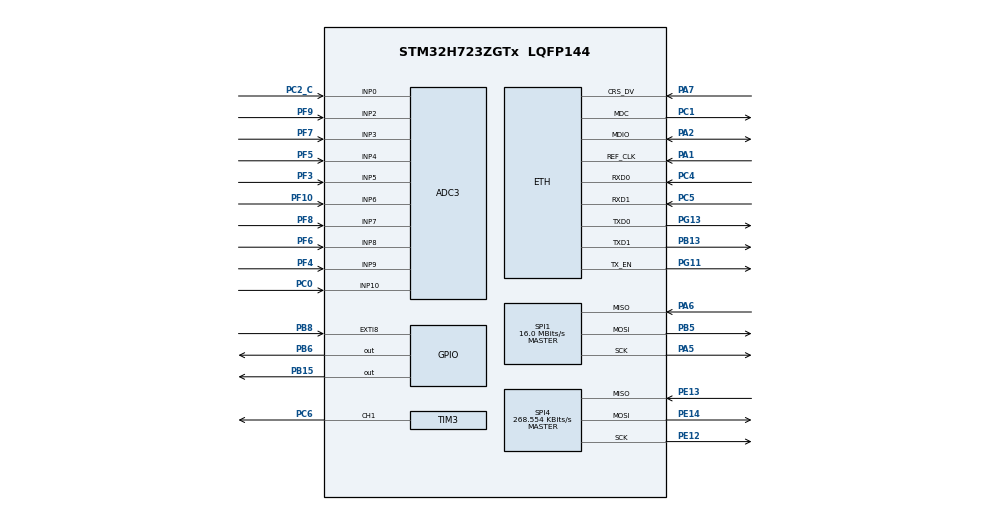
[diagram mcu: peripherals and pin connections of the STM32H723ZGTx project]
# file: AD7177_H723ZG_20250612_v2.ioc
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ADC3.Channel-0\#ChannelRegularConversion=ADC_CHANNEL_10
ADC3.Channel-1\#ChannelRegularConversion=ADC_CHANNEL_0
ADC3.Channel-10\#ChannelRegularConversion=ADC_CHANNEL_VREFINT
ADC3.Channel-2\#ChannelRegularConversion=ADC_CHANNEL_6
ADC3.Channel-3\#ChannelRegularConversion=ADC_CHANNEL_9
ADC3.Channel-4\#ChannelRegularConversion=ADC_CHANNEL_4
ADC3.Channel-5\#ChannelRegularConversion=ADC_CHANNEL_8
ADC3.Channel-6\#ChannelRegularConversion=ADC_CHANNEL_5
ADC3.Channel-7\#ChannelRegularConversion=ADC_CHANNEL_7
ADC3.Channel-8\#ChannelRegularConversion=ADC_CHANNEL_3
ADC3.Channel-9\#ChannelRegularConversion=ADC_CHANNEL_2
ADC3.DMAContinuousRequests=ENABLE
ADC3.EOCSelection=ADC_EOC_SEQ_CONV
ADC3.ExternalTrigConv=ADC_EXTERNALTRIG_T3_TRGO
ADC3.NbrOfConversion=11
ADC3.NbrOfConversionFlag=1
ADC3.OffsetNumber-0\#ChannelRegularConversion=ADC_OFFSET_NONE
ADC3.OffsetNumber-1\#ChannelRegularConversion=ADC_OFFSET_NONE
ADC3.OffsetNumber-10\#ChannelRegularConversion=ADC_OFFSET_NONE
ADC3.OffsetNumber-2\#ChannelRegularConversion=ADC_OFFSET_NONE
ADC3.OffsetNumber-3\#ChannelRegularConversion=ADC_OFFSET_NONE
ADC3.OffsetNumber-4\#ChannelRegularConversion=ADC_OFFSET_NONE
ADC3.OffsetNumber-5\#ChannelRegularConversion=ADC_OFFSET_NONE
ADC3.OffsetNumber-6\#ChannelRegularConversion=ADC_OFFSET_NONE
ADC3.OffsetNumber-7\#ChannelRegularConversion=ADC_OFFSET_NONE
ADC3.OffsetNumber-8\#ChannelRegularConversion=ADC_OFFSET_NONE
ADC3.OffsetNumber-9\#ChannelRegularConversion=ADC_OFFSET_NONE
ADC3.OffsetSign-0\#ChannelRegularConversion=ADC3_OFFSET_SIGN_NEGATIVE
ADC3.OffsetSign-1\#ChannelRegularConversion=ADC3_OFFSET_SIGN_NEGATIVE
ADC3.OffsetSign-10\#ChannelRegularConversion=ADC3_OFFSET_SIGN_NEGATIVE
ADC3.OffsetSign-2\#ChannelRegularConversion=ADC3_OFFSET_SIGN_NEGATIVE
ADC3.OffsetSign-3\#ChannelRegularConversion=ADC3_OFFSET_SIGN_NEGATIVE
ADC3.OffsetSign-4\#ChannelRegularConversion=ADC3_OFFSET_SIGN_NEGATIVE
ADC3.OffsetSign-5\#ChannelRegularConversion=ADC3_OFFSET_SIGN_NEGATIVE
ADC3.OffsetSign-6\#ChannelRegularConversion=ADC3_OFFSET_SIGN_NEGATIVE
ADC3.OffsetSign-7\#ChannelRegularConversion=ADC3_OFFSET_SIGN_NEGATIVE
ADC3.OffsetSign-8\#ChannelRegularConversion=ADC3_OFFSET_SIGN_NEGATIVE
ADC3.OffsetSign-9\#ChannelRegularConversion=ADC3_OFFSET_SIGN_NEGATIVE
ADC3.OversamplingMode=ENABLE
ADC3.Rank-0\#ChannelRegularConversion=1
ADC3.Rank-1\#ChannelRegularConversion=2
ADC3.Rank-10\#ChannelRegularConversion=11
ADC3.Rank-2\#ChannelRegularConversion=3
ADC3.Rank-3\#ChannelRegularConversion=4
ADC3.Rank-4\#ChannelRegularConversion=5
ADC3.Rank-5\#ChannelRegularConversion=6
ADC3.Rank-6\#ChannelRegularConversion=7
ADC3.Rank-7\#ChannelRegularConversion=8
ADC3.Rank-8\#ChannelRegularConversion=9
ADC3.Rank-9\#ChannelRegularConversion=10
ADC3.Ratio=ADC3_OVERSAMPLING_RATIO_128
ADC3.RightBitShift=ADC_RIGHTBITSHIFT_7
ADC3.SamplingTime-0\#ChannelRegularConversion=ADC3_SAMPLETIME_640CYCLES_5
ADC3.SamplingTime-1\#ChannelRegularConversion=ADC3_SAMPLETIME_640CYCLES_5
ADC3.SamplingTime-10\#ChannelRegularConversion=ADC3_SAMPLETIME_640CYCLES_5
ADC3.SamplingTime-2\#ChannelRegularConversion=ADC3_SAMPLETIME_640CYCLES_5
ADC3.SamplingTime-3\#ChannelRegularConversion=ADC3_SAMPLETIME_640CYCLES_5
ADC3.SamplingTime-4\#ChannelRegularConversion=ADC3_SAMPLETIME_640CYCLES_5
ADC3.SamplingTime-5\#ChannelRegularConversion=ADC3_SAMPLETIME_640CYCLES_5
ADC3.SamplingTime-6\#ChannelRegularConversion=ADC3_SAMPLETIME_640CYCLES_5
ADC3.SamplingTime-7\#ChannelRegularConversion=ADC3_SAMPLETIME_640CYCLES_5
ADC3.SamplingTime-8\#ChannelRegularConversion=ADC3_SAMPLETIME_640CYCLES_5
ADC3.SamplingTime-9\#ChannelRegularConversion=ADC3_SAMPLETIME_640CYCLES_5
Bdma.ADC3.0.Direction=DMA_PERIPH_TO_MEMORY
Bdma.ADC3.0.EventEnable=DISABLE
Bdma.ADC3.0.Instance=BDMA_Channel0
Bdma.ADC3.0.MemDataAlignment=DMA_MDATAALIGN_HALFWORD
Bdma.ADC3.0.MemInc=DMA_MINC_ENABLE
Bdma.ADC3.0.Mode=DMA_CIRCULAR
Bdma.ADC3.0.PeriphDataAlignment=DMA_PDATAALIGN_HALFWORD
Bdma.ADC3.0.PeriphInc=DMA_PINC_DISABLE
Bdma.ADC3.0.Polarity=HAL_DMAMUX_REQ_GEN_RISING
Bdma.ADC3.0.Priority=DMA_PRIORITY_HIGH
Bdma.ADC3.0.RequestNumber=1
Bdma.ADC3.0.SignalID=NONE
Bdma.ADC3.0.SyncEnable=DISABLE
Bdma.ADC3.0.SyncPolarity=HAL_DMAMUX_SYNC_NO_EVENT
Bdma.ADC3.0.SyncRequestNumber=1
Bdma.ADC3.0.SyncSignalID=NONE
Bdma.Request0=ADC3
Bdma.RequestsNb=1
CORTEX_M7.AccessPermission-Cortex_Memory_Protection_Unit_Region1_Settings=MPU_REGION_FULL_ACCESS
CORTEX_M7.AccessPermission-Cortex_Memory_Protection_Unit_Region2_Settings=MPU_REGION_FULL_ACCESS
CORTEX_M7.AccessPermission-Cortex_Memory_Protection_Unit_Region3_Settings=MPU_REGION_FULL_ACCESS
CORTEX_M7.BaseAddress-Cortex_Memory_Protection_Unit_Region1_Settings=0x30000000
CORTEX_M7.BaseAddress-Cortex_Memory_Protection_Unit_Region2_Settings=0x30000200
CORTEX_M7.BaseAddress-Cortex_Memory_Protection_Unit_Region3_Settings=0x38000000
CORTEX_M7.CPU_DCache=Enabled
CORTEX_M7.CPU_ICache=Enabled
CORTEX_M7.DisableExec-Cortex_Memory_Protection_Unit_Region0_Settings=MPU_INSTRUCTION_ACCESS_DISABLE
CORTEX_M7.DisableExec-Cortex_Memory_Protection_Unit_Region1_Settings=MPU_INSTRUCTION_ACCESS_DISABLE
CORTEX_M7.DisableExec-Cortex_Memory_Protection_Unit_Region2_Settings=MPU_INSTRUCTION_ACCESS_DISABLE
CORTEX_M7.Enable-Cortex_Memory_Protection_Unit_Region0_Settings=MPU_REGION_ENABLE
CORTEX_M7.Enable-Cortex_Memory_Protection_Unit_Region1_Settings=MPU_REGION_ENABLE
CORTEX_M7.Enable-Cortex_Memory_Protection_Unit_Region2_Settings=MPU_REGION_ENABLE
CORTEX_M7.Enable-Cortex_Memory_Protection_Unit_Region3_Settings=MPU_REGION_ENABLE
CORTEX_M7.IsBufferable-Cortex_Memory_Protection_Unit_Region1_Settings=MPU_ACCESS_BUFFERABLE
CORTEX_M7.IsBufferable-Cortex_Memory_Protection_Unit_Region3_Settings=MPU_ACCESS_BUFFERABLE
CORTEX_M7.IsShareable-Cortex_Memory_Protection_Unit_Region0_Settings=MPU_ACCESS_SHAREABLE
CORTEX_M7.IsShareable-Cortex_Memory_Protection_Unit_Region1_Settings=MPU_ACCESS_SHAREABLE
CORTEX_M7.IsShareable-Cortex_Memory_Protection_Unit_Region2_Settings=MPU_ACCESS_NOT_SHAREABLE
CORTEX_M7.IsShareable-Cortex_Memory_Protection_Unit_Region3_Settings=MPU_ACCESS_SHAREABLE
CORTEX_M7.MPU_Control=MPU_PRIVILEGED_DEFAULT
CORTEX_M7.Size-Cortex_Memory_Protection_Unit_Region0_Settings=MPU_REGION_SIZE_4GB
CORTEX_M7.Size-Cortex_Memory_Protection_Unit_Region1_Settings=MPU_REGION_SIZE_1KB
CORTEX_M7.Size-Cortex_Memory_Protection_Unit_Region2_Settings=MPU_REGION_SIZE_64KB
CORTEX_M7.Size-Cortex_Memory_Protection_Unit_Region3_Settings=MPU_REGION_SIZE_16KB
CORTEX_M7.SubRegionDisable-Cortex_Memory_Protection_Unit_Region0_Settings=0x87
CORTEX_M7.TypeExtField-Cortex_Memory_Protection_Unit_Region1_Settings=MPU_TEX_LEVEL0
CORTEX_M7.TypeExtField-Cortex_Memory_Protection_Unit_Region2_Settings=MPU_TEX_LEVEL1
Dma.Request0=SPI4_TX
Dma.Request1=SPI4_RX
Dma.Request2=SPI1_RX
Dma.Request3=SPI1_TX
Dma.SPI1_RX.2.Direction=DMA_PERIPH_TO_MEMORY
Dma.SPI1_RX.2.EventEnable=DISABLE
Dma.SPI1_RX.2.FIFOMode=DMA_FIFOMODE_DISABLE
Dma.SPI1_RX.2.Instance=DMA1_Stream2
Dma.SPI1_RX.2.MemDataAlignment=DMA_MDATAALIGN_BYTE
Dma.SPI1_RX.2.MemInc=DMA_MINC_ENABLE
Dma.SPI1_RX.2.Mode=DMA_NORMAL
Dma.SPI1_RX.2.PeriphDataAlignment=DMA_PDATAALIGN_BYTE
Dma.SPI1_RX.2.PeriphInc=DMA_PINC_DISABLE
Dma.SPI1_RX.2.Polarity=HAL_DMAMUX_REQ_GEN_RISING
Dma.SPI1_RX.2.Priority=DMA_PRIORITY_VERY_HIGH
Dma.SPI1_RX.2.RequestNumber=1
Dma.SPI1_RX.2.SignalID=NONE
Dma.SPI1_RX.2.SyncEnable=DISABLE
Dma.SPI1_RX.2.SyncPolarity=HAL_DMAMUX_SYNC_NO_EVENT
Dma.SPI1_RX.2.SyncRequestNumber=1
Dma.SPI1_RX.2.SyncSignalID=NONE
Dma.SPI1_TX.3.Direction=DMA_MEMORY_TO_PERIPH
Dma.SPI1_TX.3.EventEnable=DISABLE
Dma.SPI1_TX.3.FIFOMode=DMA_FIFOMODE_DISABLE
Dma.SPI1_TX.3.Instance=DMA1_Stream3
Dma.SPI1_TX.3.MemDataAlignment=DMA_MDATAALIGN_BYTE
Dma.SPI1_TX.3.MemInc=DMA_MINC_ENABLE
Dma.SPI1_TX.3.Mode=DMA_NORMAL
Dma.SPI1_TX.3.PeriphDataAlignment=DMA_PDATAALIGN_BYTE
Dma.SPI1_TX.3.PeriphInc=DMA_PINC_DISABLE
Dma.SPI1_TX.3.Polarity=HAL_DMAMUX_REQ_GEN_RISING
Dma.SPI1_TX.3.Priority=DMA_PRIORITY_VERY_HIGH
Dma.SPI1_TX.3.RequestNumber=1
Dma.SPI1_TX.3.SignalID=NONE
Dma.SPI1_TX.3.SyncEnable=DISABLE
Dma.SPI1_TX.3.SyncPolarity=HAL_DMAMUX_SYNC_NO_EVENT
Dma.SPI1_TX.3.SyncRequestNumber=1
Dma.SPI1_TX.3.SyncSignalID=NONE
Dma.SPI4_RX.1.Direction=DMA_PERIPH_TO_MEMORY
Dma.SPI4_RX.1.EventEnable=DISABLE
Dma.SPI4_RX.1.FIFOMode=DMA_FIFOMODE_DISABLE
Dma.SPI4_RX.1.Instance=DMA1_Stream1
Dma.SPI4_RX.1.MemDataAlignment=DMA_MDATAALIGN_BYTE
Dma.SPI4_RX.1.MemInc=DMA_MINC_ENABLE
Dma.SPI4_RX.1.Mode=DMA_NORMAL
Dma.SPI4_RX.1.PeriphDataAlignment=DMA_PDATAALIGN_BYTE
Dma.SPI4_RX.1.PeriphInc=DMA_PINC_DISABLE
Dma.SPI4_RX.1.Polarity=HAL_DMAMUX_REQ_GEN_RISING
Dma.SPI4_RX.1.Priority=DMA_PRIORITY_VERY_HIGH
Dma.SPI4_RX.1.RequestNumber=1
Dma.SPI4_RX.1.SignalID=NONE
Dma.SPI4_RX.1.SyncEnable=DISABLE
Dma.SPI4_RX.1.SyncPolarity=HAL_DMAMUX_SYNC_NO_EVENT
Dma.SPI4_RX.1.SyncRequestNumber=1
Dma.SPI4_RX.1.SyncSignalID=NONE
Dma.SPI4_TX.0.Direction=DMA_MEMORY_TO_PERIPH
Dma.SPI4_TX.0.EventEnable=DISABLE
Dma.SPI4_TX.0.FIFOMode=DMA_FIFOMODE_DISABLE
Dma.SPI4_TX.0.Instance=DMA1_Stream0
Dma.SPI4_TX.0.MemDataAlignment=DMA_MDATAALIGN_BYTE
Dma.SPI4_TX.0.MemInc=DMA_MINC_ENABLE
Dma.SPI4_TX.0.Mode=DMA_NORMAL
Dma.SPI4_TX.0.PeriphDataAlignment=DMA_PDATAALIGN_BYTE
Dma.SPI4_TX.0.PeriphInc=DMA_PINC_DISABLE
Dma.SPI4_TX.0.Polarity=HAL_DMAMUX_REQ_GEN_RISING
Dma.SPI4_TX.0.Priority=DMA_PRIORITY_VERY_HIGH
Dma.SPI4_TX.0.RequestNumber=1
Dma.SPI4_TX.0.SignalID=NONE
Dma.SPI4_TX.0.SyncEnable=DISABLE
Dma.SPI4_TX.0.SyncPolarity=HAL_DMAMUX_SYNC_NO_EVENT
Dma.SPI4_TX.0.SyncRequestNumber=1
Dma.SPI4_TX.0.SyncSignalID=NONE
ETH.MediaInterface=HAL_ETH_RMII_MODE
ETH.RxBufferAddress=0x30000200
ETH.TxDescAddress=0x30000060
FREERTOS.INCLUDE_vTaskDelayUntil=1
FREERTOS.Tasks01=defaultTask,24,256,StartDefaultTask,Default,NULL,Dynamic,NULL,NULL;ethernetTask,40,256,startEthernetTask,Default,NULL,Dynamic,NULL,NULL
FREERTOS.configTOTAL_HEAP_SIZE=30720
FREERTOS.configUSE_NEWLIB_REENTRANT=1
LWIP.BSP.number=1
LWIP.GATEWAY_ADDRESS=010.020.001.003
LWIP.IP_ADDRESS=010.020.003.003
LWIP.LWIP_DHCP=0
LWIP.LWIP_RAM_HEAP_POINTER=0x30000200
LWIP.MEM_SIZE=10*1024
LWIP.NETMASK_ADDRESS=255.255.000.000
LWIP.TCP_MSS=1460
LWIP.TCP_SND_BUF=5840
LWIP.TCP_SND_QUEUELEN=16
LWIP.Version=v2.1.2_Cube
LWIP0.BSP.STBoard=false
LWIP0.BSP.api=BSP_COMPONENT_DRIVER
LWIP0.BSP.component=LAN8742
LWIP0.BSP.instance=LAN8742
LWIP0.BSP.name=Driver_PHY
LWIP0.BSP.semaphore=S_LAN8742
LWIP0.BSP.solution=LAN8742
Mcu.Family=STM32H7
Mcu.Name=STM32H723ZGTx
Mcu.Package=LQFP144
NVIC.BDMA_Channel0_IRQn=true\:5\:0\:false\:false\:true\:true\:false\:true\:true
NVIC.DMA1_Stream0_IRQn=true\:5\:0\:false\:false\:true\:true\:false\:true\:true
NVIC.DMA1_Stream1_IRQn=true\:5\:0\:false\:false\:true\:true\:false\:true\:true
NVIC.DMA1_Stream2_IRQn=true\:5\:0\:false\:false\:true\:true\:false\:true\:true
NVIC.DMA1_Stream3_IRQn=true\:5\:0\:false\:false\:true\:true\:false\:true\:true
NVIC.ETH_IRQn=true\:5\:0\:false\:false\:true\:true\:true\:true\:true
NVIC.EXTI9_5_IRQn=true\:6\:0\:true\:false\:true\:true\:true\:true\:true
NVIC.PriorityGroup=NVIC_PRIORITYGROUP_4
NVIC.SPI1_IRQn=true\:5\:0\:false\:false\:true\:true\:true\:true\:true
NVIC.SPI4_IRQn=true\:5\:0\:false\:false\:true\:true\:false\:true\:true
NVIC.TIM2_IRQn=true\:5\:0\:false\:false\:true\:false\:true\:true\:true
NVIC.TIM6_DAC_IRQn=true\:15\:0\:false\:false\:true\:false\:false\:true\:true
NVIC.TimeBase=TIM6_DAC_IRQn
NVIC.TimeBaseIP=TIM6
PA1.GPIO_Speed=GPIO_SPEED_FREQ_VERY_HIGH
PA1.Mode=RMII
PA1.Signal=ETH_REF_CLK
PA2.GPIO_Speed=GPIO_SPEED_FREQ_VERY_HIGH
PA2.Mode=RMII
PA2.Signal=ETH_MDIO
PA5.Mode=Full_Duplex_Master
PA5.Signal=SPI1_SCK
PA6.Mode=Full_Duplex_Master
PA6.Signal=SPI1_MISO
PA7.GPIO_Speed=GPIO_SPEED_FREQ_VERY_HIGH
PA7.Mode=RMII
PA7.Signal=ETH_CRS_DV
PB13.GPIO_Speed=GPIO_SPEED_FREQ_VERY_HIGH
PB13.Mode=RMII
PB13.Signal=ETH_TXD1
PB15.Signal=GPIO_Output
PB5.Mode=Full_Duplex_Master
PB5.Signal=SPI1_MOSI
PB6.GPIO_Speed=GPIO_SPEED_FREQ_VERY_HIGH
PB6.Signal=GPIO_Output
PB8.GPIO_ModeDefaultEXTI=GPIO_MODE_IT_FALLING
PB8.GPIO_PuPd=GPIO_PULLUP
PB8.Signal=GPXTI8
PC0.Signal=ADCx_INP10
PC1.GPIO_Speed=GPIO_SPEED_FREQ_VERY_HIGH
PC1.Mode=RMII
PC1.Signal=ETH_MDC
PC2_C.Mode=IN0-Single-Ended
PC2_C.Signal=ADC3_INP0
PC4.GPIO_Speed=GPIO_SPEED_FREQ_VERY_HIGH
PC4.Mode=RMII
PC4.Signal=ETH_RXD0
PC5.GPIO_Speed=GPIO_SPEED_FREQ_VERY_HIGH
PC5.Mode=RMII
PC5.Signal=ETH_RXD1
PC6.GPIO_PuPd=GPIO_PULLUP
PC6.Signal=S_TIM3_CH1
PE12.Mode=Full_Duplex_Master
PE12.Signal=SPI4_SCK
PE13.Mode=Full_Duplex_Master
PE13.Signal=SPI4_MISO
PE14.Mode=Full_Duplex_Master
PE14.Signal=SPI4_MOSI
PF10.Mode=IN6-Single-Ended
PF10.Signal=ADC3_INP6
PF3.Mode=IN5-Single-Ended
PF3.Signal=ADC3_INP5
PF4.Mode=IN9-Single-Ended
PF4.Signal=ADC3_INP9
PF5.Mode=IN4-Single-Ended
PF5.Signal=ADC3_INP4
PF6.Mode=IN8-Single-Ended
PF6.Signal=ADC3_INP8
PF7.Mode=IN3-Single-Ended
PF7.Signal=ADC3_INP3
PF8.Mode=IN7-Single-Ended
PF8.Signal=ADC3_INP7
PF9.Mode=IN2-Single-Ended
PF9.Signal=ADC3_INP2
PG11.GPIO_Speed=GPIO_SPEED_FREQ_VERY_HIGH
PG11.Mode=RMII
PG11.Signal=ETH_TX_EN
PG13.GPIO_Speed=GPIO_SPEED_FREQ_VERY_HIGH
PG13.Mode=RMII
PG13.Signal=ETH_TXD0
PH0-OSC_IN.Mode=HSE-External-Clock-Source
PH0-OSC_IN.Signal=RCC_OSC_IN
ProjectManager.HeapSize=0x200
ProjectManager.StackSize=0x400
ProjectManager.TargetToolchain=STM32CubeIDE
RCC.ADCFreq_Value=12500000
RCC.APB1Freq_Value=137500000
RCC.APB2Freq_Value=68750000
RCC.APB3Freq_Value=137500000
RCC.APB4Freq_Value=137500000
RCC.CortexFreq_Value=550000000
RCC.D1PPRE=RCC_APB3_DIV2
RCC.D2PPRE1=RCC_APB1_DIV2
RCC.D2PPRE2=RCC_APB2_DIV4
RCC.D3PPRE=RCC_APB4_DIV2
RCC.DIVM1=4
RCC.DIVM2=1
RCC.DIVN1=275
RCC.DIVN2=25
RCC.DIVP1=1
RCC.DIVP2=16
RCC.DIVQ1=4
RCC.DIVQ2=16
RCC.HCLKFreq_Value=275000000
RCC.HPRE=RCC_HCLK_DIV2
RCC.HSE_VALUE=8000000
RCC.PLLFRACN=0
RCC.PLLSourceVirtual=RCC_PLLSOURCE_HSE
RCC.SPI123CLockSelection=RCC_SPI123CLKSOURCE_CLKP
RCC.SYSCLKFreq_VALUE=550000000
RCC.SYSCLKSource=RCC_SYSCLKSOURCE_PLLCLK
RCC.USBCLockSelection=RCC_USBCLKSOURCE_HSI48
RCC.USBFreq_Value=48000000
SH.ADCx_INP10.0=ADC3_INP10,IN10-Single-Ended
SH.S_TIM3_CH1.0=TIM3_CH1,PWM Generation1 CH1
SPI1.BaudRatePrescaler=SPI_BAUDRATEPRESCALER_4
SPI1.CLKPhase=SPI_PHASE_2EDGE
SPI1.CLKPolarity=SPI_POLARITY_HIGH
SPI1.CalculateBaudRate=16.0 MBits/s
SPI1.DataSize=SPI_DATASIZE_8BIT
SPI1.Direction=SPI_DIRECTION_2LINES
SPI1.MasterKeepIOState=SPI_MASTER_KEEP_IO_STATE_ENABLE
SPI1.Mode=SPI_MODE_MASTER
SPI1.VirtualType=VM_MASTER
SPI4.BaudRatePrescaler=SPI_BAUDRATEPRESCALER_256
SPI4.CLKPhase=SPI_PHASE_2EDGE
SPI4.CLKPolarity=SPI_POLARITY_HIGH
SPI4.CalculateBaudRate=268.554 KBits/s
SPI4.DataSize=SPI_DATASIZE_8BIT
SPI4.Direction=SPI_DIRECTION_2LINES
SPI4.MasterKeepIOState=SPI_MASTER_KEEP_IO_STATE_DISABLE
SPI4.Mode=SPI_MODE_MASTER
SPI4.VirtualType=VM_MASTER
TIM1.Channel-Output\ Compare1\ No\ Output=TIM_CHANNEL_1
TIM1.Prescaler=1375-1
TIM2.Channel-PWM\ Generation1\ No\ Output=TIM_CHANNEL_1
TIM2.Period=1000-1
TIM2.Prescaler=275-1
TIM2.TIM_MasterOutputTrigger=TIM_TRGO_RESET
TIM23.Prescaler=275-1
TIM3.Channel-PWM\ Generation1\ CH1=TIM_CHANNEL_1
TIM3.OCPolarity_1=TIM_OCPOLARITY_HIGH
TIM3.Period=10000-1
TIM3.Prescaler=2750-1
TIM3.Pulse-PWM\ Generation1\ CH1=500
TIM3.TIM_MasterOutputTrigger=TIM_TRGO_UPDATE
VP_ADC3_Vref_Input.Mode=IN-Vrefint
VP_FREERTOS_VS_CMSIS_V2.Mode=CMSIS_V2
VP_LWIP_VS_Enabled.Mode=Enabled
VP_MEMORYMAP_VS_MEMORYMAP.Mode=CurAppReg
VP_SYS_VS_tim6.Mode=TIM6
VP_TIM1_VS_ClockSourceINT.Mode=Internal
VP_TIM1_VS_no_output1.Mode=Output Compare1 No Output
VP_TIM23_VS_ClockSourceINT.Mode=Internal
VP_TIM2_VS_ClockSourceINT.Mode=Internal
VP_TIM2_VS_no_output1.Mode=PWM Generation1 No Output
VP_TIM3_VS_ClockSourceINT.Mode=Internal
VREF+.Mode=InternalMode
VREF+.Signal=VREFBUF_OUT
VREFBUF.TrimmingMode=USER_TRIMMING
VREFBUF.TrimmingValue=18
board=NUCLEO-H723ZG

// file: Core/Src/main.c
/* USER CODE BEGIN Header */
/**
 ******************************************************************************
 * @file           : main.c
 * @brief          : Main program body
 ******************************************************************************
 * @attention
 *
 * Copyright (c) 2024 STMicroelectronics.
 * All rights reserved.
 *
 * This software is licensed under terms that can be found in the LICENSE file
 * in the root directory of this software component.
 * If no LICENSE file comes with this software, it is provided AS-IS.
 *
 ******************************************************************************
 */
/* USER CODE END Header */
#include "main.h"
#include "cmsis_os.h"
#include "lwip.h"

/* USER CODE BEGIN Includes */
#include "lwip/udp.h"
#include <string.h>
#include <stdbool.h>
#include <stddef.h>
#include "stm32h7xx_it.h"
#include "AD7177_registers.h"
#include "net_config.h"

/* USER CODE END Includes */

/* USER CODE BEGIN PD */

#define HK_SYNC_STR "HKPK"
#define HK_VERSION  1

#define ACCEL_SYNC_STR "ACCL"
#define ACCEL_VERSION  1

#define PKT_WORDS 601

/* USER CODE END PD */

ADC_HandleTypeDef hadc3;
DMA_HandleTypeDef hdma_adc3;

SPI_HandleTypeDef hspi1;
SPI_HandleTypeDef hspi4;
DMA_HandleTypeDef hdma_spi1_rx;
DMA_HandleTypeDef hdma_spi1_tx;
DMA_HandleTypeDef hdma_spi4_tx;
DMA_HandleTypeDef hdma_spi4_rx;

TIM_HandleTypeDef htim1;
TIM_HandleTypeDef htim2;
TIM_HandleTypeDef htim3;
TIM_HandleTypeDef htim23;

/* Definitions for defaultTask */
osThreadId_t defaultTaskHandle;
const osThreadAttr_t defaultTask_attributes = {
  .name = "defaultTask",
  .stack_size = 256 * 4,
  .priority = (osPriority_t) osPriorityNormal,
};
/* Definitions for ethernetTask */
osThreadId_t ethernetTaskHandle;
const osThreadAttr_t ethernetTask_attributes = {
  .name = "ethernetTask",
  .stack_size = 256 * 4,
  .priority = (osPriority_t) osPriorityHigh,
};
/* USER CODE BEGIN PV */
//PUT SETUP STUFF HERE

// Ping-pong packet buffers: each packet is 601 uint16_t words
#define PKT_WORDS 601
static uint16_t pkt_buf[2][PKT_WORDS];
static volatile uint8_t write_buf = 0;      // ISR writes into this buffer (0 or 1)
static volatile uint8_t ready_buf = 0xFF;   // Published by ISR when a packet is complete
static volatile uint16_t accum_words = 0;   // Words accumulated in current write_buf

uint8_t rxBuffer24bit[5];
static uint8_t g_txBuffer24bit_IT[5] = {AD7177_READ_DATA_REG, 0,0,0,0 };
// --- ADC3 ← DMA target buffer (one regular sequence worth of samples) ---
#define ADC3_SCAN_LEN (11u)   // Must match hadc3.Init.NbrOfConversion
// 32B align for D-Cache maintenance on STM32H7

__attribute__((section(".RAM_D3"), aligned(32))) volatile uint16_t adc3_dma_buf[ADC3_SCAN_LEN];

// Housekeeping latest snapshot captured at 110 Hz in the ADC DMA callback
typedef struct {
  uint32_t tick32;               // TIM23 snapshot
  uint16_t ch[ADC3_SCAN_LEN];    // 11 channels, raw 12-bit codes
} hk_snapshot_t;

typedef struct {
  uint8_t  sync[4];   // e.g. "HKPK"
  uint8_t  version;    // e.g. 1
  uint8_t  reserved[3];// pad to 8B boundary, room for flags
  uint32_t seq;
  uint32_t tick32;
  uint16_t ch[ADC3_SCAN_LEN];
} __attribute__((packed)) hk_pkt_t;

//Small accel data header for differentiating packet types
typedef struct {
  uint8_t  sync[4];     // "ACCL"
  uint8_t  version;     // e.g. 1
  uint8_t  reserved[3]; // pad to 8B
  // existing payload follows (spiData[0..600])
} __attribute__((packed)) accel_hdr_t;

static volatile hk_snapshot_t g_hk_latest;   // written in ISR, read by task
static uint32_t g_hk_seq = 0;                // 10 Hz packet sequence

volatile bool g_init_done = false;
volatile bool g_acc_send_req = false;
volatile bool g_hk_send_req = false;
volatile bool g_spi_inflight = false;

volatile uint32_t sampleNum = 0;

volatile uint32_t channel_data[4] = {0};      // Holds raw ADC values
volatile uint8_t  channel_ready[4] = {0};     // Flags to know when each channel has been updated

volatile uint32_t timer23val;

uint8_t resetSequence[8] = {0xFF, 0xFF, 0xFF, 0xFF, 0xFF, 0xFF, 0xFF, 0xFF};

/* USER CODE END PV */

void SystemClock_Config(void);
void PeriphCommonClock_Config(void);
static void MPU_Config(void);
static void MX_GPIO_Init(void);
static void MX_DMA_Init(void);
static void MX_BDMA_Init(void);
static void MX_TIM2_Init(void);
static void MX_SPI4_Init(void);
static void MX_TIM23_Init(void);
static void MX_TIM1_Init(void);
static void MX_SPI1_Init(void);
static void MX_TIM3_Init(void);
static void MX_ADC3_Init(void);
void StartDefaultTask(void *argument);
void startEthernetTask(void *argument);

/* USER CODE BEGIN PFP */
uint32_t AD7177_ReadRegister(uint8_t reg, uint8_t num_bytes);
void AD7177_WriteRegister(uint8_t reg, uint32_t value, uint8_t num_bytes);
void initializeAD7177Board();

/* USER CODE END PFP */

int main(void)
{

  /* MPU Configuration--------------------------------------------------------*/
  MPU_Config();

  /* Enable the CPU Cache */

  /* Enable I-Cache---------------------------------------------------------*/
  SCB_EnableICache();

  /* Enable D-Cache---------------------------------------------------------*/
  SCB_EnableDCache();

  /* MCU Configuration--------------------------------------------------------*/

  /* Reset of all peripherals, Initializes the Flash interface and the Systick. */
  HAL_Init();

  /* Configure the system clock */
  SystemClock_Config();

  /* Configure the peripherals common clocks */
  PeriphCommonClock_Config();

  /* Initialize all configured peripherals */
  MX_GPIO_Init();
  MX_DMA_Init();
  MX_BDMA_Init();
  MX_TIM2_Init();
  MX_SPI4_Init();
  MX_TIM23_Init();
  MX_TIM1_Init();
  MX_SPI1_Init();
  MX_TIM3_Init();
  MX_ADC3_Init();
  /* USER CODE BEGIN 2 */
  HAL_Delay(500); //Wait for AD7177 board to power up
  HAL_GPIO_WritePin(GPIOB, GPIO_PIN_6, GPIO_PIN_RESET);
  HAL_SPI_Transmit(&hspi1, (uint8_t*)resetSequence, 8, 50);
  HAL_GPIO_WritePin(GPIOB, GPIO_PIN_6, GPIO_PIN_SET);
  /* USER CODE END 2 */

  /* Init scheduler */
  osKernelInitialize();

  /* Create the thread(s) */
  /* creation of defaultTask */
  defaultTaskHandle = osThreadNew(StartDefaultTask, NULL, &defaultTask_attributes);

  /* creation of ethernetTask */
  ethernetTaskHandle = osThreadNew(startEthernetTask, NULL, &ethernetTask_attributes);

  /* Start scheduler */
  osKernelStart();

  /* We should never get here as control is now taken by the scheduler */

  /* Infinite loop */
  while (1)
    {

    }
}

void SystemClock_Config(void)
{
  RCC_OscInitTypeDef RCC_OscInitStruct = {0};
  RCC_ClkInitTypeDef RCC_ClkInitStruct = {0};

  /** Supply configuration update enable
  */
  HAL_PWREx_ConfigSupply(PWR_LDO_SUPPLY);

  /** Configure the main internal regulator output voltage
  */
  __HAL_PWR_VOLTAGESCALING_CONFIG(PWR_REGULATOR_VOLTAGE_SCALE0);

  while(!__HAL_PWR_GET_FLAG(PWR_FLAG_VOSRDY)) {}

  /** Initializes the RCC Oscillators according to the specified parameters
  * in the RCC_OscInitTypeDef structure.
  */
  RCC_OscInitStruct.OscillatorType = RCC_OSCILLATORTYPE_HSI|RCC_OSCILLATORTYPE_HSE;
  RCC_OscInitStruct.HSEState = RCC_HSE_BYPASS;
  RCC_OscInitStruct.HSIState = RCC_HSI_DIV1;
  RCC_OscInitStruct.HSICalibrationValue = 64;
  RCC_OscInitStruct.PLL.PLLState = RCC_PLL_ON;
  RCC_OscInitStruct.PLL.PLLSource = RCC_PLLSOURCE_HSE;
  RCC_OscInitStruct.PLL.PLLM = 4;
  RCC_OscInitStruct.PLL.PLLN = 275;
  RCC_OscInitStruct.PLL.PLLP = 1;
  RCC_OscInitStruct.PLL.PLLQ = 4;
  RCC_OscInitStruct.PLL.PLLR = 2;
  RCC_OscInitStruct.PLL.PLLRGE = RCC_PLL1VCIRANGE_1;
  RCC_OscInitStruct.PLL.PLLVCOSEL = RCC_PLL1VCOWIDE;
  RCC_OscInitStruct.PLL.PLLFRACN = 0;
  if (HAL_RCC_OscConfig(&RCC_OscInitStruct) != HAL_OK)
  {
    Error_Handler();
  }

  /** Initializes the CPU, AHB and APB buses clocks
  */
  RCC_ClkInitStruct.ClockType = RCC_CLOCKTYPE_HCLK|RCC_CLOCKTYPE_SYSCLK
                              |RCC_CLOCKTYPE_PCLK1|RCC_CLOCKTYPE_PCLK2
                              |RCC_CLOCKTYPE_D3PCLK1|RCC_CLOCKTYPE_D1PCLK1;
  RCC_ClkInitStruct.SYSCLKSource = RCC_SYSCLKSOURCE_PLLCLK;
  RCC_ClkInitStruct.SYSCLKDivider = RCC_SYSCLK_DIV1;
  RCC_ClkInitStruct.AHBCLKDivider = RCC_HCLK_DIV2;
  RCC_ClkInitStruct.APB3CLKDivider = RCC_APB3_DIV2;
  RCC_ClkInitStruct.APB1CLKDivider = RCC_APB1_DIV2;
  RCC_ClkInitStruct.APB2CLKDivider = RCC_APB2_DIV4;
  RCC_ClkInitStruct.APB4CLKDivider = RCC_APB4_DIV2;

  if (HAL_RCC_ClockConfig(&RCC_ClkInitStruct, FLASH_LATENCY_3) != HAL_OK)
  {
    Error_Handler();
  }
}

void PeriphCommonClock_Config(void)
{
  RCC_PeriphCLKInitTypeDef PeriphClkInitStruct = {0};

  /** Initializes the peripherals clock
  */
  PeriphClkInitStruct.PeriphClockSelection = RCC_PERIPHCLK_CKPER;
  PeriphClkInitStruct.CkperClockSelection = RCC_CLKPSOURCE_HSI;
  if (HAL_RCCEx_PeriphCLKConfig(&PeriphClkInitStruct) != HAL_OK)
  {
    Error_Handler();
  }
}

static void MX_ADC3_Init(void)
{

  ADC_ChannelConfTypeDef sConfig = {0};

  /** Common config
  */
  hadc3.Instance = ADC3;
  hadc3.Init.ClockPrescaler = ADC_CLOCK_ASYNC_DIV1;
  hadc3.Init.Resolution = ADC_RESOLUTION_12B;
  hadc3.Init.DataAlign = ADC3_DATAALIGN_RIGHT;
  hadc3.Init.ScanConvMode = ADC_SCAN_ENABLE;
  hadc3.Init.EOCSelection = ADC_EOC_SEQ_CONV;
  hadc3.Init.LowPowerAutoWait = DISABLE;
  hadc3.Init.ContinuousConvMode = DISABLE;
  hadc3.Init.NbrOfConversion = 11;
  hadc3.Init.DiscontinuousConvMode = DISABLE;
  hadc3.Init.ExternalTrigConv = ADC_EXTERNALTRIG_T3_TRGO;
  hadc3.Init.ExternalTrigConvEdge = ADC_EXTERNALTRIGCONVEDGE_RISING;
  hadc3.Init.DMAContinuousRequests = ENABLE;
  hadc3.Init.SamplingMode = ADC_SAMPLING_MODE_NORMAL;
  hadc3.Init.ConversionDataManagement = ADC_CONVERSIONDATA_DR;
  hadc3.Init.Overrun = ADC_OVR_DATA_PRESERVED;
  hadc3.Init.LeftBitShift = ADC_LEFTBITSHIFT_NONE;
  hadc3.Init.OversamplingMode = ENABLE;
  hadc3.Init.Oversampling.Ratio = ADC3_OVERSAMPLING_RATIO_128;
  hadc3.Init.Oversampling.RightBitShift = ADC_RIGHTBITSHIFT_7;
  hadc3.Init.Oversampling.TriggeredMode = ADC_TRIGGEREDMODE_SINGLE_TRIGGER;
  hadc3.Init.Oversampling.OversamplingStopReset = ADC_REGOVERSAMPLING_CONTINUED_MODE;
  if (HAL_ADC_Init(&hadc3) != HAL_OK)
  {
    Error_Handler();
  }

  /** Configure Regular Channel
  */
  sConfig.Channel = ADC_CHANNEL_10;
  sConfig.Rank = ADC_REGULAR_RANK_1;
  sConfig.SamplingTime = ADC3_SAMPLETIME_640CYCLES_5;
  sConfig.SingleDiff = ADC_SINGLE_ENDED;
  sConfig.OffsetNumber = ADC_OFFSET_NONE;
  sConfig.Offset = 0;
  sConfig.OffsetSign = ADC3_OFFSET_SIGN_NEGATIVE;
  if (HAL_ADC_ConfigChannel(&hadc3, &sConfig) != HAL_OK)
  {
    Error_Handler();
  }

  /** Configure Regular Channel
  */
  sConfig.Channel = ADC_CHANNEL_0;
  sConfig.Rank = ADC_REGULAR_RANK_2;
  if (HAL_ADC_ConfigChannel(&hadc3, &sConfig) != HAL_OK)
  {
    Error_Handler();
  }

  /** Configure Regular Channel
  */
  sConfig.Channel = ADC_CHANNEL_6;
  sConfig.Rank = ADC_REGULAR_RANK_3;
  if (HAL_ADC_ConfigChannel(&hadc3, &sConfig) != HAL_OK)
  {
    Error_Handler();
  }

  /** Configure Regular Channel
  */
  sConfig.Channel = ADC_CHANNEL_9;
  sConfig.Rank = ADC_REGULAR_RANK_4;
  if (HAL_ADC_ConfigChannel(&hadc3, &sConfig) != HAL_OK)
  {
    Error_Handler();
  }

  /** Configure Regular Channel
  */
  sConfig.Channel = ADC_CHANNEL_4;
  sConfig.Rank = ADC_REGULAR_RANK_5;
  if (HAL_ADC_ConfigChannel(&hadc3, &sConfig) != HAL_OK)
  {
    Error_Handler();
  }

  /** Configure Regular Channel
  */
  sConfig.Channel = ADC_CHANNEL_8;
  sConfig.Rank = ADC_REGULAR_RANK_6;
  if (HAL_ADC_ConfigChannel(&hadc3, &sConfig) != HAL_OK)
  {
    Error_Handler();
  }

  /** Configure Regular Channel
  */
  sConfig.Channel = ADC_CHANNEL_5;
  sConfig.Rank = ADC_REGULAR_RANK_7;
  if (HAL_ADC_ConfigChannel(&hadc3, &sConfig) != HAL_OK)
  {
    Error_Handler();
  }

  /** Configure Regular Channel
  */
  sConfig.Channel = ADC_CHANNEL_7;
  sConfig.Rank = ADC_REGULAR_RANK_8;
  if (HAL_ADC_ConfigChannel(&hadc3, &sConfig) != HAL_OK)
  {
    Error_Handler();
  }

  /** Configure Regular Channel
  */
  sConfig.Channel = ADC_CHANNEL_3;
  sConfig.Rank = ADC_REGULAR_RANK_9;
  if (HAL_ADC_ConfigChannel(&hadc3, &sConfig) != HAL_OK)
  {
    Error_Handler();
  }

  /** Configure Regular Channel
  */
  sConfig.Channel = ADC_CHANNEL_2;
  sConfig.Rank = ADC_REGULAR_RANK_10;
  if (HAL_ADC_ConfigChannel(&hadc3, &sConfig) != HAL_OK)
  {
    Error_Handler();
  }

  /** Configure Regular Channel
  */
  sConfig.Channel = ADC_CHANNEL_VREFINT;
  sConfig.Rank = ADC_REGULAR_RANK_11;
  if (HAL_ADC_ConfigChannel(&hadc3, &sConfig) != HAL_OK)
  {
    Error_Handler();
  }
  /* USER CODE BEGIN ADC3_Init 2 */
  HAL_ADCEx_Calibration_Start(&hadc3, ADC_CALIB_OFFSET, ADC_SINGLE_ENDED);
  /* USER CODE END ADC3_Init 2 */

}

static void MX_SPI1_Init(void)
{

  /* SPI1 parameter configuration*/
  hspi1.Instance = SPI1;
  hspi1.Init.Mode = SPI_MODE_MASTER;
  hspi1.Init.Direction = SPI_DIRECTION_2LINES;
  hspi1.Init.DataSize = SPI_DATASIZE_8BIT;
  hspi1.Init.CLKPolarity = SPI_POLARITY_HIGH;
  hspi1.Init.CLKPhase = SPI_PHASE_2EDGE;
  hspi1.Init.NSS = SPI_NSS_SOFT;
  hspi1.Init.BaudRatePrescaler = SPI_BAUDRATEPRESCALER_4;
  hspi1.Init.FirstBit = SPI_FIRSTBIT_MSB;
  hspi1.Init.TIMode = SPI_TIMODE_DISABLE;
  hspi1.Init.CRCCalculation = SPI_CRCCALCULATION_DISABLE;
  hspi1.Init.CRCPolynomial = 0x0;
  hspi1.Init.NSSPMode = SPI_NSS_PULSE_ENABLE;
  hspi1.Init.NSSPolarity = SPI_NSS_POLARITY_LOW;
  hspi1.Init.FifoThreshold = SPI_FIFO_THRESHOLD_01DATA;
  hspi1.Init.TxCRCInitializationPattern = SPI_CRC_INITIALIZATION_ALL_ZERO_PATTERN;
  hspi1.Init.RxCRCInitializationPattern = SPI_CRC_INITIALIZATION_ALL_ZERO_PATTERN;
  hspi1.Init.MasterSSIdleness = SPI_MASTER_SS_IDLENESS_00CYCLE;
  hspi1.Init.MasterInterDataIdleness = SPI_MASTER_INTERDATA_IDLENESS_00CYCLE;
  hspi1.Init.MasterReceiverAutoSusp = SPI_MASTER_RX_AUTOSUSP_DISABLE;
  hspi1.Init.MasterKeepIOState = SPI_MASTER_KEEP_IO_STATE_ENABLE;
  hspi1.Init.IOSwap = SPI_IO_SWAP_DISABLE;
  if (HAL_SPI_Init(&hspi1) != HAL_OK)
  {
    Error_Handler();
  }

}

static void MX_SPI4_Init(void)
{

  /* SPI4 parameter configuration*/
  hspi4.Instance = SPI4;
  hspi4.Init.Mode = SPI_MODE_MASTER;
  hspi4.Init.Direction = SPI_DIRECTION_2LINES;
  hspi4.Init.DataSize = SPI_DATASIZE_8BIT;
  hspi4.Init.CLKPolarity = SPI_POLARITY_HIGH;
  hspi4.Init.CLKPhase = SPI_PHASE_2EDGE;
  hspi4.Init.NSS = SPI_NSS_SOFT;
  hspi4.Init.BaudRatePrescaler = SPI_BAUDRATEPRESCALER_256;
  hspi4.Init.FirstBit = SPI_FIRSTBIT_MSB;
  hspi4.Init.TIMode = SPI_TIMODE_DISABLE;
  hspi4.Init.CRCCalculation = SPI_CRCCALCULATION_DISABLE;
  hspi4.Init.CRCPolynomial = 0x0;
  hspi4.Init.NSSPMode = SPI_NSS_PULSE_ENABLE;
  hspi4.Init.NSSPolarity = SPI_NSS_POLARITY_LOW;
  hspi4.Init.FifoThreshold = SPI_FIFO_THRESHOLD_01DATA;
  hspi4.Init.TxCRCInitializationPattern = SPI_CRC_INITIALIZATION_ALL_ZERO_PATTERN;
  hspi4.Init.RxCRCInitializationPattern = SPI_CRC_INITIALIZATION_ALL_ZERO_PATTERN;
  hspi4.Init.MasterSSIdleness = SPI_MASTER_SS_IDLENESS_00CYCLE;
  hspi4.Init.MasterInterDataIdleness = SPI_MASTER_INTERDATA_IDLENESS_00CYCLE;
  hspi4.Init.MasterReceiverAutoSusp = SPI_MASTER_RX_AUTOSUSP_DISABLE;
  hspi4.Init.MasterKeepIOState = SPI_MASTER_KEEP_IO_STATE_DISABLE;
  hspi4.Init.IOSwap = SPI_IO_SWAP_DISABLE;
  if (HAL_SPI_Init(&hspi4) != HAL_OK)
  {
    Error_Handler();
  }

}

static void MX_TIM1_Init(void)
{

  TIM_ClockConfigTypeDef sClockSourceConfig = {0};
  TIM_MasterConfigTypeDef sMasterConfig = {0};
  TIM_OC_InitTypeDef sConfigOC = {0};
  TIM_BreakDeadTimeConfigTypeDef sBreakDeadTimeConfig = {0};

  htim1.Instance = TIM1;
  htim1.Init.Prescaler = 1375-1;
  htim1.Init.CounterMode = TIM_COUNTERMODE_UP;
  htim1.Init.Period = 65535;
  htim1.Init.ClockDivision = TIM_CLOCKDIVISION_DIV1;
  htim1.Init.RepetitionCounter = 0;
  htim1.Init.AutoReloadPreload = TIM_AUTORELOAD_PRELOAD_DISABLE;
  if (HAL_TIM_Base_Init(&htim1) != HAL_OK)
  {
    Error_Handler();
  }
  sClockSourceConfig.ClockSource = TIM_CLOCKSOURCE_INTERNAL;
  if (HAL_TIM_ConfigClockSource(&htim1, &sClockSourceConfig) != HAL_OK)
  {
    Error_Handler();
  }
  if (HAL_TIM_OC_Init(&htim1) != HAL_OK)
  {
    Error_Handler();
  }
  sMasterConfig.MasterOutputTrigger = TIM_TRGO_RESET;
  sMasterConfig.MasterOutputTrigger2 = TIM_TRGO2_RESET;
  sMasterConfig.MasterSlaveMode = TIM_MASTERSLAVEMODE_DISABLE;
  if (HAL_TIMEx_MasterConfigSynchronization(&htim1, &sMasterConfig) != HAL_OK)
  {
    Error_Handler();
  }
  sConfigOC.OCMode = TIM_OCMODE_TIMING;
  sConfigOC.Pulse = 0;
  sConfigOC.OCPolarity = TIM_OCPOLARITY_HIGH;
  sConfigOC.OCNPolarity = TIM_OCNPOLARITY_HIGH;
  sConfigOC.OCFastMode = TIM_OCFAST_DISABLE;
  sConfigOC.OCIdleState = TIM_OCIDLESTATE_RESET;
  sConfigOC.OCNIdleState = TIM_OCNIDLESTATE_RESET;
  if (HAL_TIM_OC_ConfigChannel(&htim1, &sConfigOC, TIM_CHANNEL_1) != HAL_OK)
  {
    Error_Handler();
  }
  sBreakDeadTimeConfig.OffStateRunMode = TIM_OSSR_DISABLE;
  sBreakDeadTimeConfig.OffStateIDLEMode = TIM_OSSI_DISABLE;
  sBreakDeadTimeConfig.LockLevel = TIM_LOCKLEVEL_OFF;
  sBreakDeadTimeConfig.DeadTime = 0;
  sBreakDeadTimeConfig.BreakState = TIM_BREAK_DISABLE;
  sBreakDeadTimeConfig.BreakPolarity = TIM_BREAKPOLARITY_HIGH;
  sBreakDeadTimeConfig.BreakFilter = 0;
  sBreakDeadTimeConfig.Break2State = TIM_BREAK2_DISABLE;
  sBreakDeadTimeConfig.Break2Polarity = TIM_BREAK2POLARITY_HIGH;
  sBreakDeadTimeConfig.Break2Filter = 0;
  sBreakDeadTimeConfig.AutomaticOutput = TIM_AUTOMATICOUTPUT_DISABLE;
  if (HAL_TIMEx_ConfigBreakDeadTime(&htim1, &sBreakDeadTimeConfig) != HAL_OK)
  {
    Error_Handler();
  }

}

static void MX_TIM2_Init(void)
{

  TIM_ClockConfigTypeDef sClockSourceConfig = {0};
  TIM_MasterConfigTypeDef sMasterConfig = {0};
  TIM_OC_InitTypeDef sConfigOC = {0};

  htim2.Instance = TIM2;
  htim2.Init.Prescaler = 275-1;
  htim2.Init.CounterMode = TIM_COUNTERMODE_UP;
  htim2.Init.Period = 1000-1;
  htim2.Init.ClockDivision = TIM_CLOCKDIVISION_DIV1;
  htim2.Init.AutoReloadPreload = TIM_AUTORELOAD_PRELOAD_DISABLE;
  if (HAL_TIM_Base_Init(&htim2) != HAL_OK)
  {
    Error_Handler();
  }
  sClockSourceConfig.ClockSource = TIM_CLOCKSOURCE_INTERNAL;
  if (HAL_TIM_ConfigClockSource(&htim2, &sClockSourceConfig) != HAL_OK)
  {
    Error_Handler();
  }
  if (HAL_TIM_PWM_Init(&htim2) != HAL_OK)
  {
    Error_Handler();
  }
  sMasterConfig.MasterOutputTrigger = TIM_TRGO_RESET;
  sMasterConfig.MasterSlaveMode = TIM_MASTERSLAVEMODE_DISABLE;
  if (HAL_TIMEx_MasterConfigSynchronization(&htim2, &sMasterConfig) != HAL_OK)
  {
    Error_Handler();
  }
  sConfigOC.OCMode = TIM_OCMODE_PWM1;
  sConfigOC.Pulse = 0;
  sConfigOC.OCPolarity = TIM_OCPOLARITY_HIGH;
  sConfigOC.OCFastMode = TIM_OCFAST_DISABLE;
  if (HAL_TIM_PWM_ConfigChannel(&htim2, &sConfigOC, TIM_CHANNEL_1) != HAL_OK)
  {
    Error_Handler();
  }

}

static void MX_TIM3_Init(void)
{

  TIM_ClockConfigTypeDef sClockSourceConfig = {0};
  TIM_MasterConfigTypeDef sMasterConfig = {0};
  TIM_OC_InitTypeDef sConfigOC = {0};

  htim3.Instance = TIM3;
  htim3.Init.Prescaler = 2750-1;
  htim3.Init.CounterMode = TIM_COUNTERMODE_UP;
  htim3.Init.Period = 10000-1;
  htim3.Init.ClockDivision = TIM_CLOCKDIVISION_DIV1;
  htim3.Init.AutoReloadPreload = TIM_AUTORELOAD_PRELOAD_DISABLE;
  if (HAL_TIM_Base_Init(&htim3) != HAL_OK)
  {
    Error_Handler();
  }
  sClockSourceConfig.ClockSource = TIM_CLOCKSOURCE_INTERNAL;
  if (HAL_TIM_ConfigClockSource(&htim3, &sClockSourceConfig) != HAL_OK)
  {
    Error_Handler();
  }
  if (HAL_TIM_PWM_Init(&htim3) != HAL_OK)
  {
    Error_Handler();
  }
  sMasterConfig.MasterOutputTrigger = TIM_TRGO_UPDATE;
  sMasterConfig.MasterSlaveMode = TIM_MASTERSLAVEMODE_DISABLE;
  if (HAL_TIMEx_MasterConfigSynchronization(&htim3, &sMasterConfig) != HAL_OK)
  {
    Error_Handler();
  }
  sConfigOC.OCMode = TIM_OCMODE_PWM1;
  sConfigOC.Pulse = 500;
  sConfigOC.OCPolarity = TIM_OCPOLARITY_HIGH;
  sConfigOC.OCFastMode = TIM_OCFAST_DISABLE;
  if (HAL_TIM_PWM_ConfigChannel(&htim3, &sConfigOC, TIM_CHANNEL_1) != HAL_OK)
  {
    Error_Handler();
  }
  HAL_TIM_MspPostInit(&htim3);

}

static void MX_TIM23_Init(void)
{

  TIM_ClockConfigTypeDef sClockSourceConfig = {0};
  TIM_MasterConfigTypeDef sMasterConfig = {0};

  htim23.Instance = TIM23;
  htim23.Init.Prescaler = 275-1;
  htim23.Init.CounterMode = TIM_COUNTERMODE_UP;
  htim23.Init.Period = 4294967295;
  htim23.Init.ClockDivision = TIM_CLOCKDIVISION_DIV1;
  htim23.Init.AutoReloadPreload = TIM_AUTORELOAD_PRELOAD_DISABLE;
  if (HAL_TIM_Base_Init(&htim23) != HAL_OK)
  {
    Error_Handler();
  }
  sClockSourceConfig.ClockSource = TIM_CLOCKSOURCE_INTERNAL;
  if (HAL_TIM_ConfigClockSource(&htim23, &sClockSourceConfig) != HAL_OK)
  {
    Error_Handler();
  }
  sMasterConfig.MasterOutputTrigger = TIM_TRGO_RESET;
  sMasterConfig.MasterSlaveMode = TIM_MASTERSLAVEMODE_DISABLE;
  if (HAL_TIMEx_MasterConfigSynchronization(&htim23, &sMasterConfig) != HAL_OK)
  {
    Error_Handler();
  }

}

static void MX_BDMA_Init(void)
{

  /* DMA controller clock enable */
  __HAL_RCC_BDMA_CLK_ENABLE();

  /* DMA interrupt init */
  /* BDMA_Channel0_IRQn interrupt configuration */
  HAL_NVIC_SetPriority(BDMA_Channel0_IRQn, 5, 0);
  HAL_NVIC_EnableIRQ(BDMA_Channel0_IRQn);

}

static void MX_DMA_Init(void)
{

  /* DMA controller clock enable */
  __HAL_RCC_DMA1_CLK_ENABLE();

  /* DMA interrupt init */
  /* DMA1_Stream0_IRQn interrupt configuration */
  HAL_NVIC_SetPriority(DMA1_Stream0_IRQn, 5, 0);
  HAL_NVIC_EnableIRQ(DMA1_Stream0_IRQn);
  /* DMA1_Stream1_IRQn interrupt configuration */
  HAL_NVIC_SetPriority(DMA1_Stream1_IRQn, 5, 0);
  HAL_NVIC_EnableIRQ(DMA1_Stream1_IRQn);
  /* DMA1_Stream2_IRQn interrupt configuration */
  HAL_NVIC_SetPriority(DMA1_Stream2_IRQn, 5, 0);
  HAL_NVIC_EnableIRQ(DMA1_Stream2_IRQn);
  /* DMA1_Stream3_IRQn interrupt configuration */
  HAL_NVIC_SetPriority(DMA1_Stream3_IRQn, 5, 0);
  HAL_NVIC_EnableIRQ(DMA1_Stream3_IRQn);

}

static void MX_GPIO_Init(void)
{
  GPIO_InitTypeDef GPIO_InitStruct = {0};

  /* GPIO Ports Clock Enable */
  __HAL_RCC_GPIOF_CLK_ENABLE();
  __HAL_RCC_GPIOH_CLK_ENABLE();
  __HAL_RCC_GPIOC_CLK_ENABLE();
  __HAL_RCC_GPIOA_CLK_ENABLE();
  __HAL_RCC_GPIOE_CLK_ENABLE();
  __HAL_RCC_GPIOB_CLK_ENABLE();
  __HAL_RCC_GPIOG_CLK_ENABLE();

  /*Configure GPIO pin Output Level */
  HAL_GPIO_WritePin(GPIOB, GPIO_PIN_15|GPIO_PIN_6, GPIO_PIN_RESET);

  /*Configure GPIO pin : PB15 */
  GPIO_InitStruct.Pin = GPIO_PIN_15;
  GPIO_InitStruct.Mode = GPIO_MODE_OUTPUT_PP;
  GPIO_InitStruct.Pull = GPIO_NOPULL;
  GPIO_InitStruct.Speed = GPIO_SPEED_FREQ_LOW;
  HAL_GPIO_Init(GPIOB, &GPIO_InitStruct);

  /*Configure GPIO pin : PB6 */
  GPIO_InitStruct.Pin = GPIO_PIN_6;
  GPIO_InitStruct.Mode = GPIO_MODE_OUTPUT_PP;
  GPIO_InitStruct.Pull = GPIO_NOPULL;
  GPIO_InitStruct.Speed = GPIO_SPEED_FREQ_VERY_HIGH;
  HAL_GPIO_Init(GPIOB, &GPIO_InitStruct);

  /*Configure GPIO pin : PB8 */
  GPIO_InitStruct.Pin = GPIO_PIN_8;
  GPIO_InitStruct.Mode = GPIO_MODE_IT_FALLING;
  GPIO_InitStruct.Pull = GPIO_PULLUP;
  HAL_GPIO_Init(GPIOB, &GPIO_InitStruct);

  /* EXTI interrupt init*/
  HAL_NVIC_SetPriority(EXTI9_5_IRQn, 6, 0);
  HAL_NVIC_EnableIRQ(EXTI9_5_IRQn);

  /* USER CODE BEGIN MX_GPIO_Init_2 */
  HAL_NVIC_DisableIRQ(EXTI9_5_IRQn);
  /* USER CODE END MX_GPIO_Init_2 */
}

/* USER CODE BEGIN 4 */

// Helper: invalidate D-Cache for an arbitrary address & size (align to 32B lines)
static inline void InvalidateDCacheByAddr_Aligned(void *addr, size_t size_bytes)
{
  uintptr_t start = (uintptr_t)addr;
  uintptr_t end   = start + size_bytes;
  start &= ~(uintptr_t)0x1Fu;               // align down to 32B
  end   = (end + 31u) & ~(uintptr_t)0x1Fu;  // align up to 32B
  SCB_InvalidateDCache_by_Addr((uint32_t*)start, (int32_t)(end - start));
}

// DMA complete callback for ADC3 regular group
void HAL_ADC_ConvCpltCallback(ADC_HandleTypeDef *hadc)
{
  if (hadc->Instance == ADC3)
  {
    // Make DMA-written samples visible to CPU before any read/use
    InvalidateDCacheByAddr_Aligned((void*)adc3_dma_buf, sizeof(adc3_dma_buf));

    // Snapshot the scan and a hardware tick for alignment
    g_hk_latest.tick32 = __HAL_TIM_GET_COUNTER(&htim23);
    for (uint32_t i = 0; i < ADC3_SCAN_LEN; i++) {
      g_hk_latest.ch[i] = adc3_dma_buf[i];
    }

    // Wake the ethernet task exactly once per scan
    g_hk_send_req = true;
    BaseType_t hpw = pdFALSE;
    vTaskNotifyGiveFromISR(ethernetTaskHandle, &hpw);
    portYIELD_FROM_ISR(hpw);

    HAL_GPIO_TogglePin(GPIOB, GPIO_PIN_15);
  }
}

void HAL_ADC_ErrorCallback(ADC_HandleTypeDef *hadc)
{
  if (hadc->Instance == ADC3)
  {
    // Optional: add diagnostics/logging breakpoint here
    __NOP();
  }
}

// EXTI Line8 External Interrupt ISR Handler CallBackFun
void HAL_GPIO_EXTI_Callback(uint16_t GPIO_Pin)
{
  if (GPIO_Pin == GPIO_PIN_8 && g_init_done) {
    if (g_spi_inflight) return; // drop edge; SPI still busy

    NVIC_DisableIRQ(EXTI9_5_IRQn);
    g_spi_inflight = true;

    HAL_StatusTypeDef rc = HAL_SPI_TransmitReceive_IT(&hspi1, g_txBuffer24bit_IT,
                                                      (uint8_t *)rxBuffer24bit, 5);
    if (rc != HAL_OK) {
      g_spi_inflight = false;
      __HAL_GPIO_EXTI_CLEAR_FLAG(GPIO_PIN_8);
      NVIC_ClearPendingIRQ(EXTI9_5_IRQn);
      NVIC_EnableIRQ(EXTI9_5_IRQn);   // don't stay masked on failure
      return;
    }
    timer23val = __HAL_TIM_GET_COUNTER(&htim23);
  }
}
void HAL_SPI_TxRxCpltCallback(SPI_HandleTypeDef *hspi)
{
  if (hspi->Instance == SPI1)
    {
      uint32_t value_24Bit =
	  (rxBuffer24bit[1] << 16) |
	  (rxBuffer24bit[2] << 8) |
	  rxBuffer24bit[3];

      uint8_t  status       = rxBuffer24bit[4];              // Bottom byte = status

      bool rdy        = !(status & 0x80);   // Bit 7: 0 = data ready
      bool adc_error  =  (status & 0x40);   // Bit 6: 1 = ADC error
      bool crc_error  =  (status & 0x20);   // Bit 5: 1 = CRC error
      uint8_t channel_id = status & 0x0F;   // Bits 3:0 = Channel ID

      // Check that the data is fresh and without error
      if (rdy && !adc_error && !crc_error && channel_id < NUM_CH_ENABLED) {
	  channel_data[channel_id] = value_24Bit; // store data temporarily
	  channel_ready[channel_id] = 1; //set that channel's ready flag high (this is different from rdy)
      }

      // Once all channels have been read, build and store packet
      if (channel_ready[0] && channel_ready[1] && channel_ready[2]) {

	  // Clear ready flags
	  for (int i = 0; i < NUM_CH_ENABLED; i++) channel_ready[i] = 0;

	  uint16_t *dst = &pkt_buf[write_buf][accum_words];

          // 3 channels -> 6 words
          for (int i = 0; i < NUM_CH_ENABLED; i++) {
              dst[i*2 + 0] = (uint16_t)(channel_data[i] & 0xFFFF);
              dst[i*2 + 1] = (uint16_t)(((channel_data[i] >> 16) & 0xFF) << 8) | (uint16_t)i;
          }
	  // Add timestamp
          dst[6] = (uint16_t)(timer23val & 0xFFFF);
          dst[7] = (uint16_t)((timer23val >> 16) & 0xFFFF);

	  //spacers (may change this later)
          dst[8] = 0xAB89;
          dst[9] = 0xEFCD;

          accum_words += 10;

          if (accum_words == 600) { // packet is ready
              pkt_buf[write_buf][600] = (uint16_t)(sampleNum & 0xFFFF);
	      sampleNum++;

	      uint8_t just_filled = write_buf;
	      write_buf ^= 1;           // flip for next accumulation
	      accum_words = 0;          // reset for new write_buf
	      ready_buf = just_filled;  // publish which buffer is ready
	      g_acc_send_req = true;
	      BaseType_t xHigherPriorityTaskWoken = pdFALSE;
	      vTaskNotifyGiveFromISR(ethernetTaskHandle, &xHigherPriorityTaskWoken); // function will set xHigherPriorityTaskWoken to pdTRUE if the unblocked task (ethernetTaskHandle) has a higher priority than the currently running task. Also unblocks task
	      portYIELD_FROM_ISR(xHigherPriorityTaskWoken); // if xHigherPriorityTaskWoken is pdTURE, scheduler will switch to the ethernetTaskHandle task as soon as the ISR completes. Otherwise, currently running task will continue to run after ISR completes
	  }
      }
      g_spi_inflight = false;
      __HAL_GPIO_EXTI_CLEAR_FLAG(GPIO_PIN_8);   // clear EXTI line pending
      //Re-enable EXTI IRQ for the next clean edge
      NVIC_ClearPendingIRQ(EXTI9_5_IRQn);
      NVIC_EnableIRQ(EXTI9_5_IRQn);
    }
}

void HAL_SPI_ErrorCallback(SPI_HandleTypeDef *hspi)
{
  if (hspi->Instance == SPI1) {
    g_spi_inflight = false;
    __HAL_GPIO_EXTI_CLEAR_FLAG(GPIO_PIN_8);
    NVIC_ClearPendingIRQ(EXTI9_5_IRQn);
    NVIC_EnableIRQ(EXTI9_5_IRQn);
  }
}

void AD7177_WriteRegister(uint8_t reg, uint32_t value, uint8_t num_bytes){
  uint8_t cmd = (reg & 0x3F);
  uint8_t tx[4] = { cmd, 0, 0, 0 };
  if (num_bytes == 3) {
      tx[1] = (value >> 16) & 0xFF;
      tx[2] = (value >> 8) & 0xFF;
      tx[3] = value & 0xFF;
  } else if (num_bytes == 2) {
      tx[1] = (value >> 8) & 0xFF;
      tx[2] = value & 0xFF;
  } else if (num_bytes == 1) {
      tx[1] = value & 0xFF;
  }
  HAL_GPIO_WritePin(GPIOB, GPIO_PIN_6, GPIO_PIN_RESET);
  HAL_SPI_Transmit(&hspi1, tx, num_bytes + 1, HAL_MAX_DELAY);
  HAL_GPIO_WritePin(GPIOB, GPIO_PIN_6, GPIO_PIN_SET);
}

uint32_t AD7177_ReadRegister(uint8_t reg, uint8_t num_bytes)
{
  uint8_t cmd = 0x40 | (reg & 0x3F);
  uint8_t tx[4] = { cmd, 0, 0, 0 };
  uint8_t rx[4] = {0};
  HAL_GPIO_WritePin(GPIOB, GPIO_PIN_6, GPIO_PIN_RESET);
  HAL_SPI_TransmitReceive(&hspi1, tx, rx, num_bytes + 1, 50);
  HAL_GPIO_WritePin(GPIOB, GPIO_PIN_6, GPIO_PIN_SET);
  uint32_t result = 0;
  for (int i = 0; i < num_bytes; ++i) {
      result = (result << 8) | rx[i + 1];
  }
  return result;
}

void initializeAD7177Board() {
  // Reset
  HAL_GPIO_WritePin(GPIOB, GPIO_PIN_6, GPIO_PIN_RESET);
  HAL_SPI_Transmit(&hspi1, (uint8_t *)resetSequence, 8, HAL_MAX_DELAY);
  HAL_GPIO_WritePin(GPIOB, GPIO_PIN_6, GPIO_PIN_SET);

  HAL_Delay(5);

  // set up ADC Mode
  AD7177_WriteRegister(AD7177_REG_ADCMODE, AD7177_ADCMODE, 2);

  // set up IF Mode, enable DATA_STAT byte, and continuous conversion mode
  AD7177_WriteRegister(AD7177_REG_IFMODE, AD7177_IFMODE, 2);

  // Configure filter mode 0
  AD7177_WriteRegister(AD7177_REG_FILTCON0, AD7177_FILTCON0, 2);

  // Configure setup mode 0
  AD7177_WriteRegister(AD7177_REG_SETUPCON0, AD7177_SETUPCON0, 2);

  // Setup channels 0 to 2
  AD7177_WriteRegister(AD7177_REG_CH0, AD7177_CH0_SETUP0, 2);
  AD7177_WriteRegister(AD7177_REG_CH1, AD7177_CH1_SETUP0, 2);
  AD7177_WriteRegister(AD7177_REG_CH2, AD7177_CH2_SETUP0, 2);
}

/* USER CODE END 4 */

void StartDefaultTask(void *argument)
{
  /* init code for LWIP */
  MX_LWIP_Init();
  /* USER CODE BEGIN 5 */

  extern struct netif gnetif;

  // Apply compile-time IP settings (overrides CubeMX static values)
  ip_addr_t ipaddr, netmask, gw;
  IP_ADDR4(&ipaddr,  NET_IPADDR0,  NET_IPADDR1,  NET_IPADDR2,  NET_IPADDR3);
  IP_ADDR4(&netmask, NET_NETMASK0, NET_NETMASK1, NET_NETMASK2, NET_NETMASK3);
  IP_ADDR4(&gw,      NET_GW0,     NET_GW1,     NET_GW2,     NET_GW3);
  netif_set_addr(&gnetif, &ipaddr, &netmask, &gw);
  netif_set_up(&gnetif);              // bring interface up
  netif_set_link_up(&gnetif);      // only if you really need to force link

  /* Infinite loop */
  for(;;)
    {
      vTaskDelete(NULL); //deletes task
    }
  /* USER CODE END 5 */
}

void startEthernetTask(void *argument)
{
  /* USER CODE BEGIN startEthernetTask */

  extern struct netif gnetif;
  //Wait for default task to set up PHY
  while (!netif_is_up(&gnetif)) {
      osDelay(1);
  }
  // Destination (PC) address from macros
  ip_addr_t pc_ip;
  IP_ADDR4(&pc_ip, NET_PCIP0, NET_PCIP1, NET_PCIP2, NET_PCIP3);

  static uint16_t last_sent_sample = 0xFFFF;  // impossible at startup

  struct udp_pcb* my_udp = udp_new();
  // Bind to our source port; using IP_ADDR_ANY lets lwIP pick the bound IP from gnetif
  udp_bind(my_udp, IP_ADDR_ANY, NET_ACCEL_SRC_PORT);
  // Set default destination
  udp_connect(my_udp, &pc_ip, NET_ACCEL_DST_PORT);

  struct pbuf* udp_buffer = NULL;

  // Start timer 23
  HAL_TIM_Base_Start(&htim23);
  // Start timer 1
  HAL_TIM_Base_Start(&htim1);
  // Start timer 2 with 1ms interrupts
  HAL_TIM_Base_Start_IT(&htim2);

  initializeAD7177Board();
  g_init_done = true;
  HAL_GPIO_WritePin(GPIOB, GPIO_PIN_6, GPIO_PIN_RESET); // pull CS low

  HAL_NVIC_EnableIRQ(EXTI9_5_IRQn); // enable interrupt for shared DOUT/RDY pin

  hk_pkt_t pkt;
  memcpy(pkt.sync, HK_SYNC_STR, 4);
  pkt.version = HK_VERSION;
  memset(pkt.reserved, 0, sizeof(pkt.reserved));

  //Start TIM3 for 110Hz ADC3 conversions
  HAL_TIM_PWM_Start(&htim3, TIM_CHANNEL_1); //Test IO
  HAL_TIM_Base_Start(&htim3);

  // --- Start ADC3 in DMA mode: one DMA burst per TIM3 TRGO (110 Hz) ---
  // Each trigger performs a full 11-rank scan -> fills adc3_dma_buf[0..10]
  HAL_StatusTypeDef status;
  status = HAL_ADC_Start_DMA(&hadc3, (uint32_t*)adc3_dma_buf, ADC3_SCAN_LEN);
  if (status != HAL_OK) {
      Error_Handler();
  }

  for (;;)
    {
      // wait for notification from the SPI callback function when a full packet is ready
      ulTaskNotifyTake(pdTRUE, portMAX_DELAY);

      // Handle any backlog before re-blocking
      while (g_acc_send_req || g_hk_send_req)
	{
	  if(g_acc_send_req)
	    {
	      g_acc_send_req = false;
	      // Consume the published ping-pong buffer (if any)
	      uint8_t rb = ready_buf;
	      if (rb <= 1) {
	          // Duplicate guard using the stamped sample number at word 600
	          uint16_t this_sample = pkt_buf[rb][600];
	          if (this_sample != last_sent_sample) {
	              last_sent_sample = this_sample;

	              // Send the data over Ethernet: header + 601 words from pkt_buf[rb]
	              udp_buffer = pbuf_alloc(PBUF_TRANSPORT,
	                                      sizeof(accel_hdr_t) + sizeof(pkt_buf[0]),
	                                      PBUF_RAM);
	              if (udp_buffer != NULL)
	              {
	                  accel_hdr_t hdr;
	                  memcpy(hdr.sync, ACCEL_SYNC_STR, 4);
	                  hdr.version = ACCEL_VERSION;
	                  memset(hdr.reserved, 0, sizeof(hdr.reserved));

	                  memcpy(udp_buffer->payload, &hdr, sizeof(hdr));
	                  memcpy((uint8_t*)udp_buffer->payload + sizeof(hdr),
	                         pkt_buf[rb], sizeof(pkt_buf[rb]));

	                  udp_send(my_udp, udp_buffer);
	                  pbuf_free(udp_buffer);
	              }
	          }
	          // mark consumed regardless; ISR will republish next full buffer
	          ready_buf = 0xFF;
	      }
	    }
	  if(g_hk_send_req)
	    {
	      g_hk_send_req = false;
	      // Snapshot the volatile structure
	      hk_snapshot_t snap;
	      snap.tick32 = g_hk_latest.tick32;
	      for (uint32_t i = 0; i < ADC3_SCAN_LEN; i++) {
		  snap.ch[i] = g_hk_latest.ch[i];
	      }

	      // Build packet
	      pkt.seq    = g_hk_seq++;
	      pkt.tick32 = snap.tick32;
	      for (uint32_t i = 0; i < ADC3_SCAN_LEN; i++) {
		  pkt.ch[i] = snap.ch[i];
	      }

	      // Send one packet per scan
	      struct pbuf* pb = pbuf_alloc(PBUF_TRANSPORT, sizeof(pkt), PBUF_RAM);
	      if (pb) {
		  memcpy(pb->payload, &pkt, sizeof(pkt));
		  udp_send(my_udp, pb);
		  pbuf_free(pb);
	      }
	    }
	  // If more notifies stacked while we were sending, consume them now
	  if (ulTaskNotifyTake(pdTRUE, 0)) {
	      // loop again with current flags (which ISRs may have set)
	      continue;
	  }
	}

    }
  /* USER CODE END startEthernetTask */
}

 /* MPU Configuration */

void MPU_Config(void)
{
  MPU_Region_InitTypeDef MPU_InitStruct = {0};

  /* Disables the MPU */
  HAL_MPU_Disable();

  /** Initializes and configures the Region and the memory to be protected
  */
  MPU_InitStruct.Enable = MPU_REGION_ENABLE;
  MPU_InitStruct.Number = MPU_REGION_NUMBER0;
  MPU_InitStruct.BaseAddress = 0x0;
  MPU_InitStruct.Size = MPU_REGION_SIZE_4GB;
  MPU_InitStruct.SubRegionDisable = 0x87;
  MPU_InitStruct.TypeExtField = MPU_TEX_LEVEL0;
  MPU_InitStruct.AccessPermission = MPU_REGION_NO_ACCESS;
  MPU_InitStruct.DisableExec = MPU_INSTRUCTION_ACCESS_DISABLE;
  MPU_InitStruct.IsShareable = MPU_ACCESS_SHAREABLE;
  MPU_InitStruct.IsCacheable = MPU_ACCESS_NOT_CACHEABLE;
  MPU_InitStruct.IsBufferable = MPU_ACCESS_NOT_BUFFERABLE;

  HAL_MPU_ConfigRegion(&MPU_InitStruct);

  /** Initializes and configures the Region and the memory to be protected
  */
  MPU_InitStruct.Number = MPU_REGION_NUMBER1;
  MPU_InitStruct.BaseAddress = 0x30000000;
  MPU_InitStruct.Size = MPU_REGION_SIZE_1KB;
  MPU_InitStruct.SubRegionDisable = 0x0;
  MPU_InitStruct.AccessPermission = MPU_REGION_FULL_ACCESS;
  MPU_InitStruct.IsBufferable = MPU_ACCESS_BUFFERABLE;

  HAL_MPU_ConfigRegion(&MPU_InitStruct);

  /** Initializes and configures the Region and the memory to be protected
  */
  MPU_InitStruct.Number = MPU_REGION_NUMBER2;
  MPU_InitStruct.BaseAddress = 0x30000200;
  MPU_InitStruct.Size = MPU_REGION_SIZE_64KB;
  MPU_InitStruct.TypeExtField = MPU_TEX_LEVEL1;
  MPU_InitStruct.IsShareable = MPU_ACCESS_NOT_SHAREABLE;
  MPU_InitStruct.IsBufferable = MPU_ACCESS_NOT_BUFFERABLE;

  HAL_MPU_ConfigRegion(&MPU_InitStruct);

  /** Initializes and configures the Region and the memory to be protected
  */
  MPU_InitStruct.Number = MPU_REGION_NUMBER3;
  MPU_InitStruct.BaseAddress = 0x38000000;
  MPU_InitStruct.Size = MPU_REGION_SIZE_16KB;
  MPU_InitStruct.TypeExtField = MPU_TEX_LEVEL0;
  MPU_InitStruct.DisableExec = MPU_INSTRUCTION_ACCESS_ENABLE;
  MPU_InitStruct.IsShareable = MPU_ACCESS_SHAREABLE;
  MPU_InitStruct.IsBufferable = MPU_ACCESS_BUFFERABLE;

  HAL_MPU_ConfigRegion(&MPU_InitStruct);
  /* Enables the MPU */
  HAL_MPU_Enable(MPU_PRIVILEGED_DEFAULT);

}

void HAL_TIM_PeriodElapsedCallback(TIM_HandleTypeDef *htim)
{
  if (htim->Instance == TIM6)
  {
    HAL_IncTick();
  }
}

void Error_Handler(void)
{
  __disable_irq();
  while (1)
    {
    }
}
